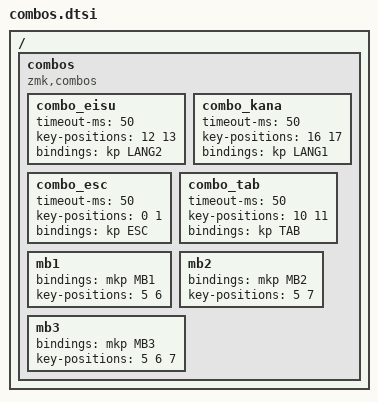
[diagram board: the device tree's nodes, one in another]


/ {
    combos {
        compatible = "zmk,combos";

        combo_eisu {
            timeout-ms = <50>;
            key-positions = <12 13>;
            bindings = <&kp LANG2>;
        };

        combo_kana {
            timeout-ms = <50>;
            key-positions = <16 17>;
            bindings = <&kp LANG1>;
        };

        combo_esc {
            timeout-ms = <50>;
            key-positions = <0 1>;
            bindings = <&kp ESC>;
        };

        combo_tab {
            timeout-ms = <50>;
            key-positions = <10 11>;
            bindings = <&kp TAB>;
        };

        mb1 {
            bindings = <&mkp MB1>;
            key-positions = <5 6>;
        };

        mb2 {
            bindings = <&mkp MB2>;
            key-positions = <5 7>;
        };

        mb3 {
            bindings = <&mkp MB3>;
            key-positions = <5 6 7>;
        };
    };
};
